# ATmega328PB register map
Vendor: Atmel; File version: 1.0
CPU: other r0p0, little endian, no MPU, no FPU, 4 interrupt priority bits
Registers are 8-bit, read-write, reset 0x0 unless marked. A register's access mark holds for its fields unless they carry their own. Offsets are from the block's base; [hi:lo] are bit positions.

## TC2 — Timer/Counter, 8-bit Async
Base 0x00800037
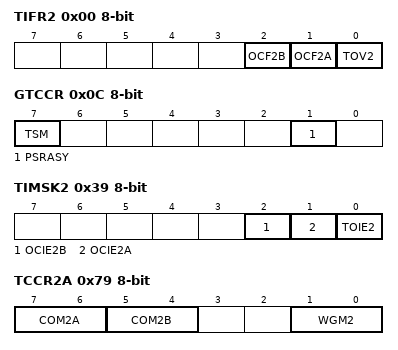
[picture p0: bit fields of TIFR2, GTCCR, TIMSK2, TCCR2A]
0x00 TIFR2 — Timer/Counter Interrupt Flag Register (read-only for debugger)
  [2] OCF2B — Output Compare Flag 2B
  [1] OCF2A — Output Compare Flag 2A
  [0] TOV2 — Timer/Counter2 Overflow Flag
0x0C GTCCR — General Timer Counter Control register
  [7] TSM — Timer/Counter Synchronization Mode
  [1] PSRASY — Prescaler Reset Timer/Counter2
0x39 TIMSK2 — Timer/Counter Interrupt Mask register
  [2] OCIE2B — Timer/Counter2 Output Compare Match B Interrupt Enable
  [1] OCIE2A — Timer/Counter2 Output Compare Match A Interrupt Enable
  [0] TOIE2 — Timer/Counter2 Overflow Interrupt Enable
0x79 TCCR2A — Timer/Counter2 Control Register A
  [7:6] COM2A — Compare Output Mode bits
  [5:4] COM2B — Compare Output Mode bits
  [1:0] WGM2 — Waveform Generation Mode
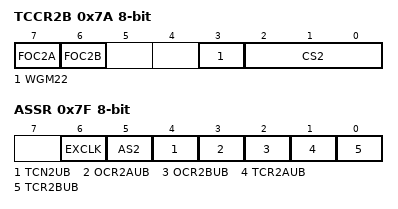
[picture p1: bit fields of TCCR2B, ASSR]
0x7A TCCR2B — Timer/Counter2 Control Register B
  [7] FOC2A — Force Output Compare A
  [6] FOC2B — Force Output Compare B
  [3] WGM22 — Waveform Generation Mode
  [2:0] CS2 — Clock Select bits
    0=NO_CLOCK_SOURCE_STOPPED; 1=RUNNING_NO_PRESCALING; 2=RUNNING_CLK_8; 3=RUNNING_CLK_32; 4=RUNNING_CLK_64; 5=RUNNING_CLK_128; 6=RUNNING_CLK_256; 7=RUNNING_CLK_1024
0x7B TCNT2 — Timer/Counter2
0x7C OCR2A — Timer/Counter2 Output Compare Register A
0x7D OCR2B — Timer/Counter2 Output Compare Register B
0x7F ASSR — Asynchronous Status Register
  [6] EXCLK — Enable External Clock Input
  [5] AS2 — Asynchronous Timer/Counter2
  [4] TCN2UB — Timer/Counter2 Update Busy
  [3] OCR2AUB — Output Compare Register2 Update Busy
  [2] OCR2BUB — Output Compare Register 2 Update Busy
  [1] TCR2AUB — Timer/Counter Control Register2 Update Busy
  [0] TCR2BUB — Timer/Counter Control Register2 Update Busy

## TC3
Base 0x00800038
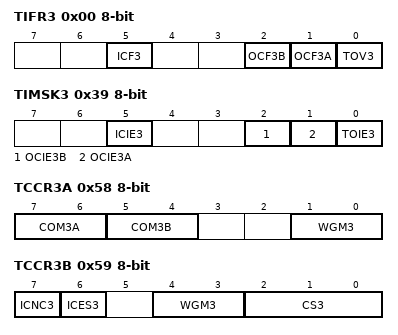
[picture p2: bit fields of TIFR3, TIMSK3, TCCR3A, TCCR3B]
0x00 TIFR3 — Timer/Counter3 Interrupt Flag register (read-only for debugger)
  [5] ICF3 — Timer/Counter3 Input Capture Flag
  [2] OCF3B — Timer/Counter3 Output Compare B Match Flag
  [1] OCF3A — Timer/Counter3 Output Compare A Match Flag
  [0] TOV3 — Timer/Counter3 Overflow Flag
0x39 TIMSK3 — Timer/Counter3 Interrupt Mask Register
  [5] ICIE3 — Timer/Counter3 Input Capture Interrupt Enable
  [2] OCIE3B — Timer/Counter3 Output Compare B Match Interrupt Enable
  [1] OCIE3A — Timer/Counter3 Output Compare A Match Interrupt Enable
  [0] TOIE3 — Timer/Counter3 Overflow Interrupt Enable
0x58 TCCR3A — Timer/Counter3 Control Register A
  [7:6] COM3A — Compare Output Mode 3A bits
  [5:4] COM3B — Compare Output Mode 3B bits
  [1:0] WGM3 — Waveform Generation Mode
0x59 TCCR3B — Timer/Counter3 Control Register B
  [7] ICNC3 — Input Capture Noise Canceler
  [6] ICES3 — Input Capture Edge Select
  [4:3] WGM3 — Waveform Generation Mode
  [2:0] CS3 — Clock Select bits
    0=NO_CLOCK_SOURCE_STOPPED; 1=RUNNING_NO_PRESCALING; 2=RUNNING_CLK_8; 3=RUNNING_CLK_64; 4=RUNNING_CLK_256; 5=RUNNING_CLK_1024; 6=RUNNING_EXTCLK_TN_FALLING_EDGE; 7=RUNNING_EXTCLK_TN_RISING_EDGE
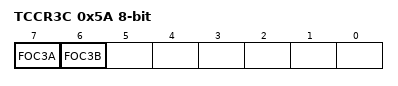
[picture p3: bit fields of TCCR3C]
0x5A TCCR3C — Timer/Counter3 Control Register C (write-only for debugger)
  [7] FOC3A — Force Output Compare for Channel A
  [6] FOC3B — Force Output Compare for Channel B
0x5C TCNT3 16-bit (reset mask 0xFF) — Timer/Counter3 Bytes
0x5E ICR3 16-bit (reset mask 0xFF) — Timer/Counter3 Input Capture Register Bytes
0x60 OCR3A 16-bit (reset mask 0xFF) — Timer/Counter3 Output Compare Register Bytes
0x62 OCR3B 16-bit (reset mask 0xFF) — Timer/Counter3 Output Compare Register Bytes

## TC4
Base 0x00800039
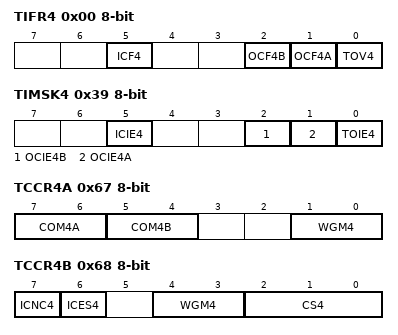
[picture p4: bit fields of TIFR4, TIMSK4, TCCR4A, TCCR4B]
0x00 TIFR4 — Timer/Counter4 Interrupt Flag register (read-only for debugger)
  [5] ICF4 — Timer/Counter4 Input Capture Flag
  [2] OCF4B — Timer/Counter4 Output Compare B Match Flag
  [1] OCF4A — Timer/Counter4 Output Compare A Match Flag
  [0] TOV4 — Timer/Counter4 Overflow Flag
0x39 TIMSK4 — Timer/Counter4 Interrupt Mask Register
  [5] ICIE4 — Timer/Counter4 Input Capture Interrupt Enable
  [2] OCIE4B — Timer/Counter4 Output Compare B Match Interrupt Enable
  [1] OCIE4A — Timer/Counter4 Output Compare A Match Interrupt Enable
  [0] TOIE4 — Timer/Counter4 Overflow Interrupt Enable
0x67 TCCR4A — Timer/Counter4 Control Register A
  [7:6] COM4A — Compare Output Mode 4A bits
  [5:4] COM4B — Compare Output Mode 4B bits
  [1:0] WGM4 — Waveform Generation Mode
0x68 TCCR4B — Timer/Counter4 Control Register B
  [7] ICNC4 — Input Capture Noise Canceler
  [6] ICES4 — Input Capture Edge Select
  [4:3] WGM4 — Waveform Generation Mode
  [2:0] CS4 — Clock Select bits
    0=NO_CLOCK_SOURCE_STOPPED; 1=RUNNING_NO_PRESCALING; 2=RUNNING_CLK_8; 3=RUNNING_CLK_64; 4=RUNNING_CLK_256; 5=RUNNING_CLK_1024; 6=RUNNING_EXTCLK_TN_FALLING_EDGE; 7=RUNNING_EXTCLK_TN_RISING_EDGE
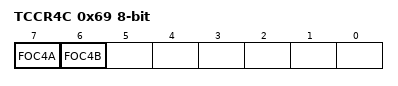
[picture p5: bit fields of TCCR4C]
0x69 TCCR4C — Timer/Counter4 Control Register C (write-only for debugger)
  [7] FOC4A — Force Output Compare for Channel A
  [6] FOC4B — Force Output Compare for Channel B
0x6B TCNT4 16-bit (reset mask 0xFF) — Timer/Counter4 Bytes
0x6D ICR4 16-bit (reset mask 0xFF) — Timer/Counter4 Input Capture Register Bytes
0x6F OCR4A 16-bit (reset mask 0xFF) — Timer/Counter4 Output Compare Register Bytes
0x71 OCR4B 16-bit (reset mask 0xFF) — Timer/Counter4 Output Compare Register Bytes
